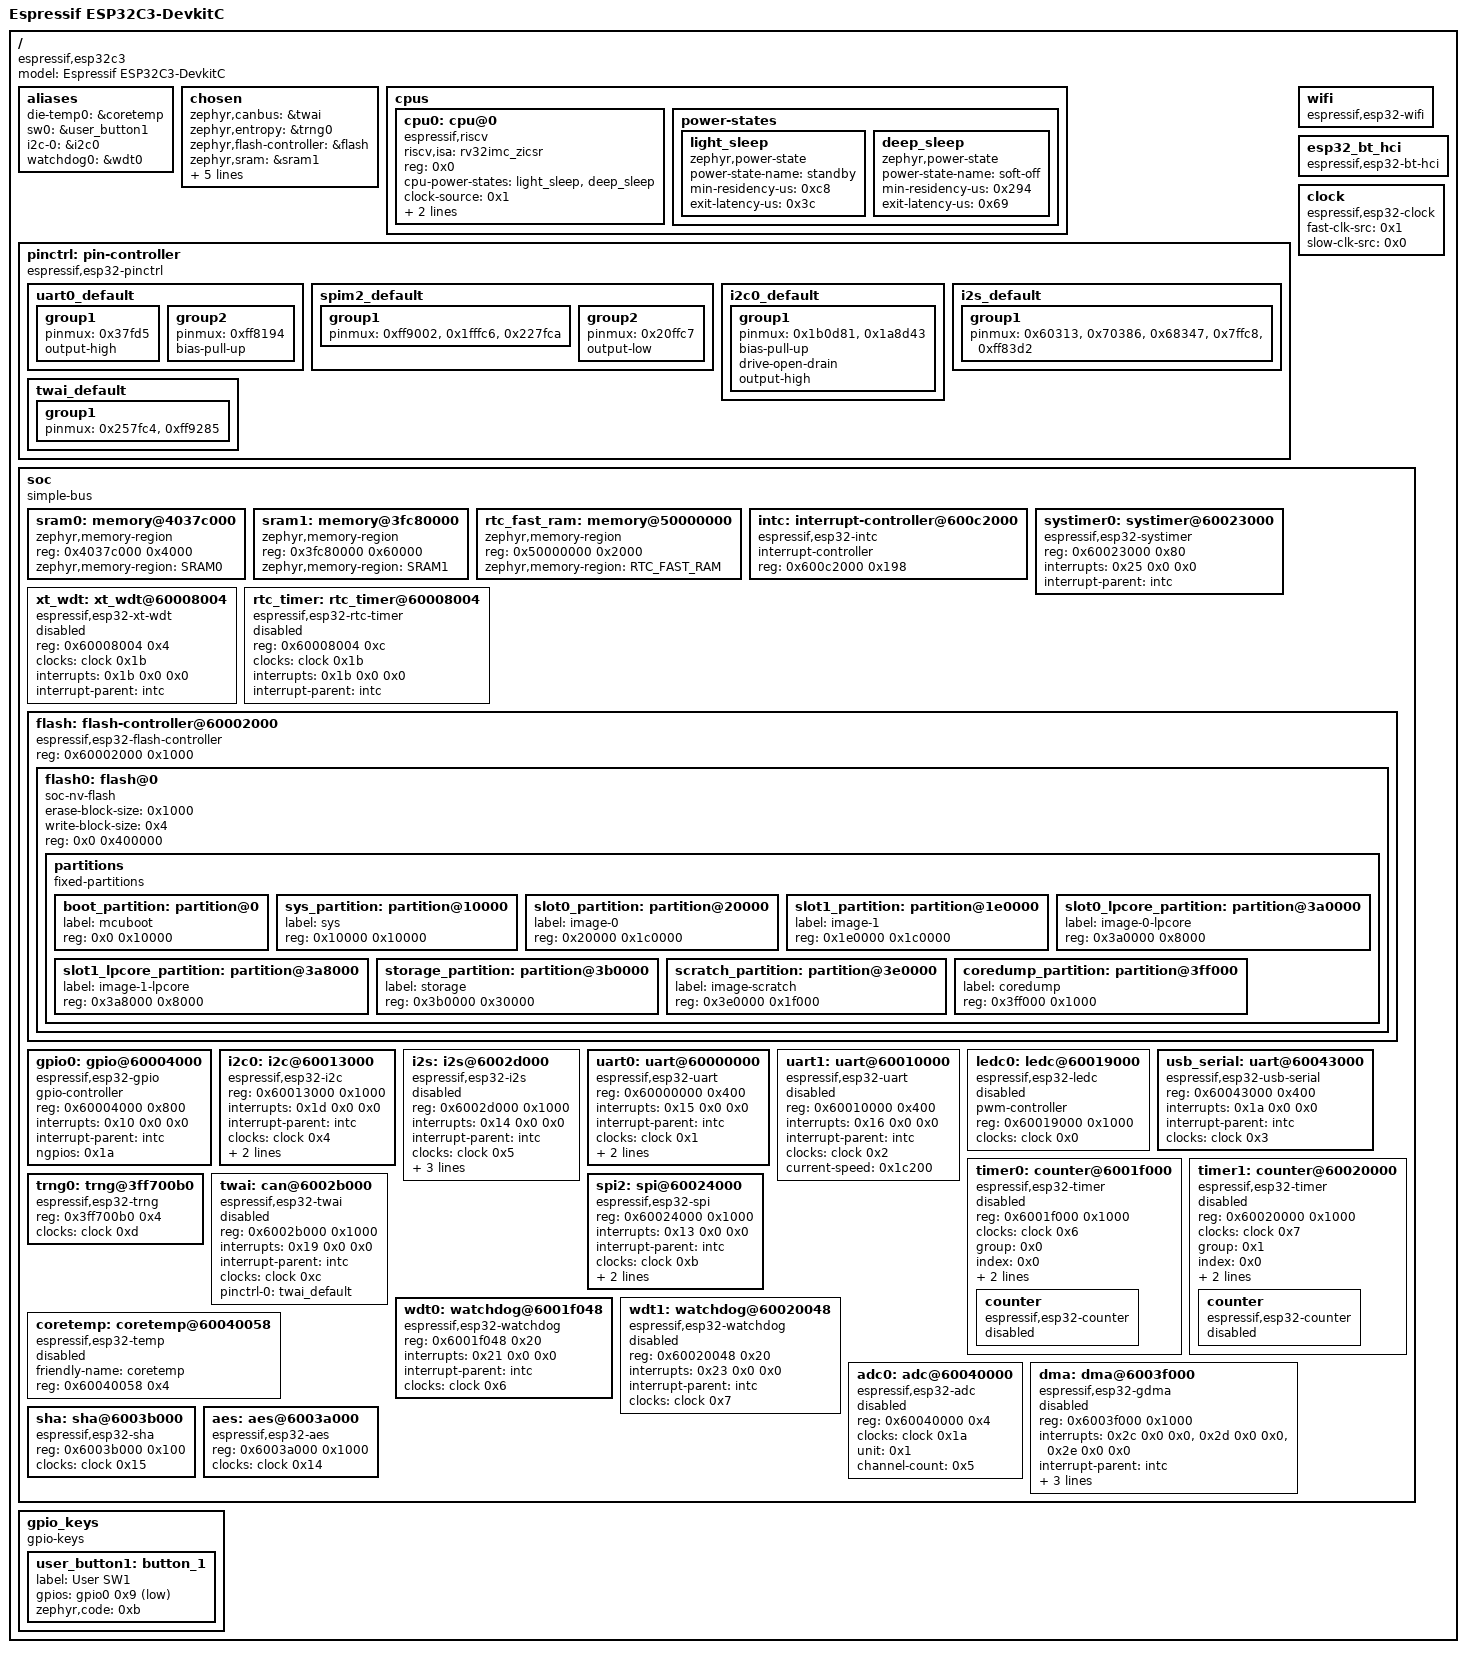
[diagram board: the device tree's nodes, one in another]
/dts-v1/;

/* node '/' defined in zephyr/dts/riscv/espressif/esp32c3/esp32c3_common.dtsi:15 */
/ {
	#address-cells = < 0x1 >;            /* in zephyr/dts/riscv/espressif/esp32c3/esp32c3_common.dtsi:16 */
	#size-cells = < 0x1 >;               /* in zephyr/dts/riscv/espressif/esp32c3/esp32c3_common.dtsi:17 */
	model = "Espressif ESP32C3-DevkitC"; /* in zephyr/boards/espressif/esp32c3_devkitc/esp32c3_devkitc.dts:15 */
	compatible = "espressif,esp32c3";    /* in zephyr/boards/espressif/esp32c3_devkitc/esp32c3_devkitc.dts:16 */

	/* node '/aliases' defined in zephyr/dts/riscv/espressif/esp32c3/esp32c3_common.dtsi:19 */
	aliases {
		die-temp0 = &coretemp; /* in zephyr/dts/riscv/espressif/esp32c3/esp32c3_common.dtsi:20 */
		sw0 = &user_button1;   /* in zephyr/boards/espressif/esp32c3_devkitc/esp32c3_devkitc.dts:28 */
		i2c-0 = &i2c0;         /* in zephyr/boards/espressif/esp32c3_devkitc/esp32c3_devkitc.dts:29 */
		watchdog0 = &wdt0;     /* in zephyr/boards/espressif/esp32c3_devkitc/esp32c3_devkitc.dts:30 */
	};

	/* node '/chosen' defined in zephyr/dts/riscv/espressif/esp32c3/esp32c3_common.dtsi:23 */
	chosen {
		zephyr,canbus = &twai;                    /* in zephyr/dts/riscv/espressif/esp32c3/esp32c3_common.dtsi:24 */
		zephyr,entropy = &trng0;                  /* in zephyr/dts/riscv/espressif/esp32c3/esp32c3_common.dtsi:25 */
		zephyr,flash-controller = &flash;         /* in zephyr/dts/riscv/espressif/esp32c3/esp32c3_common.dtsi:26 */
		zephyr,sram = &sram1;                     /* in zephyr/boards/espressif/esp32c3_devkitc/esp32c3_devkitc.dts:19 */
		zephyr,console = &uart0;                  /* in zephyr/boards/espressif/esp32c3_devkitc/esp32c3_devkitc.dts:20 */
		zephyr,shell-uart = &uart0;               /* in zephyr/boards/espressif/esp32c3_devkitc/esp32c3_devkitc.dts:21 */
		zephyr,flash = &flash0;                   /* in zephyr/boards/espressif/esp32c3_devkitc/esp32c3_devkitc.dts:22 */
		zephyr,code-partition = &slot0_partition; /* in zephyr/boards/espressif/esp32c3_devkitc/esp32c3_devkitc.dts:23 */
		zephyr,bt-hci = &esp32_bt_hci;            /* in zephyr/boards/espressif/esp32c3_devkitc/esp32c3_devkitc.dts:24 */
	};

	/* node '/cpus' defined in zephyr/dts/riscv/espressif/esp32c3/esp32c3_common.dtsi:30 */
	cpus {
		#address-cells = < 0x1 >; /* in zephyr/dts/riscv/espressif/esp32c3/esp32c3_common.dtsi:31 */
		#size-cells = < 0x0 >;    /* in zephyr/dts/riscv/espressif/esp32c3/esp32c3_common.dtsi:32 */

		/* node '/cpus/cpu@0' defined in zephyr/dts/riscv/espressif/esp32c3/esp32c3_common.dtsi:34 */
		cpu0: cpu@0 {
			device_type = "cpu";                             /* in zephyr/dts/riscv/espressif/esp32c3/esp32c3_common.dtsi:35 */
			compatible = "espressif,riscv",
			             "riscv";                            /* in zephyr/dts/riscv/espressif/esp32c3/esp32c3_common.dtsi:36 */
			riscv,isa = "rv32imc_zicsr";                     /* in zephyr/dts/riscv/espressif/esp32c3/esp32c3_common.dtsi:37 */
			reg = < 0x0 >;                                   /* in zephyr/dts/riscv/espressif/esp32c3/esp32c3_common.dtsi:38 */
			cpu-power-states = < &light_sleep &deep_sleep >; /* in zephyr/dts/riscv/espressif/esp32c3/esp32c3_common.dtsi:39 */
			clock-source = < 0x1 >;                          /* in zephyr/dts/riscv/espressif/esp32c3/esp32c3_common.dtsi:40 */
			clock-frequency = < 0x9896800 >;                 /* in zephyr/dts/riscv/espressif/esp32c3/esp32c3_common.dtsi:41 */
			xtal-freq = < 0x2625a00 >;                       /* in zephyr/dts/riscv/espressif/esp32c3/esp32c3_common.dtsi:42 */
		};

		/* node '/cpus/power-states' defined in zephyr/dts/riscv/espressif/esp32c3/esp32c3_common.dtsi:45 */
		power-states {

			/* node '/cpus/power-states/light_sleep' defined in zephyr/dts/riscv/espressif/esp32c3/esp32c3_common.dtsi:46 */
			light_sleep: light_sleep {
				compatible = "zephyr,power-state"; /* in zephyr/dts/riscv/espressif/esp32c3/esp32c3_common.dtsi:47 */
				power-state-name = "standby";      /* in zephyr/dts/riscv/espressif/esp32c3/esp32c3_common.dtsi:48 */
				min-residency-us = < 0xc8 >;       /* in zephyr/dts/riscv/espressif/esp32c3/esp32c3_common.dtsi:49 */
				exit-latency-us = < 0x3c >;        /* in zephyr/dts/riscv/espressif/esp32c3/esp32c3_common.dtsi:50 */
				phandle = < 0x1 >;                 /* in zephyr/dts/riscv/espressif/esp32c3/esp32c3_common.dtsi:39 */
			};

			/* node '/cpus/power-states/deep_sleep' defined in zephyr/dts/riscv/espressif/esp32c3/esp32c3_common.dtsi:53 */
			deep_sleep: deep_sleep {
				compatible = "zephyr,power-state"; /* in zephyr/dts/riscv/espressif/esp32c3/esp32c3_common.dtsi:54 */
				power-state-name = "soft-off";     /* in zephyr/dts/riscv/espressif/esp32c3/esp32c3_common.dtsi:55 */
				min-residency-us = < 0x294 >;      /* in zephyr/dts/riscv/espressif/esp32c3/esp32c3_common.dtsi:56 */
				exit-latency-us = < 0x69 >;        /* in zephyr/dts/riscv/espressif/esp32c3/esp32c3_common.dtsi:57 */
				phandle = < 0x2 >;                 /* in zephyr/dts/riscv/espressif/esp32c3/esp32c3_common.dtsi:39 */
			};
		};
	};

	/* node '/pin-controller' defined in zephyr/dts/riscv/espressif/esp32c3/esp32c3_common.dtsi:62 */
	pinctrl: pin-controller {
		compatible = "espressif,esp32-pinctrl"; /* in zephyr/dts/riscv/espressif/esp32c3/esp32c3_common.dtsi:63 */
		status = "okay";                        /* in zephyr/dts/riscv/espressif/esp32c3/esp32c3_common.dtsi:64 */

		/* node '/pin-controller/uart0_default' defined in zephyr/boards/espressif/esp32c3_devkitc/esp32c3_devkitc-pinctrl.dtsi:12 */
		uart0_default: uart0_default {
			phandle = < 0x8 >; /* in zephyr/boards/espressif/esp32c3_devkitc/esp32c3_devkitc.dts:47 */

			/* node '/pin-controller/uart0_default/group1' defined in zephyr/boards/espressif/esp32c3_devkitc/esp32c3_devkitc-pinctrl.dtsi:13 */
			group1 {
				pinmux = < 0x37fd5 >; /* in zephyr/boards/espressif/esp32c3_devkitc/esp32c3_devkitc-pinctrl.dtsi:14 */
				output-high;          /* in zephyr/boards/espressif/esp32c3_devkitc/esp32c3_devkitc-pinctrl.dtsi:15 */
			};

			/* node '/pin-controller/uart0_default/group2' defined in zephyr/boards/espressif/esp32c3_devkitc/esp32c3_devkitc-pinctrl.dtsi:18 */
			group2 {
				pinmux = < 0xff8194 >; /* in zephyr/boards/espressif/esp32c3_devkitc/esp32c3_devkitc-pinctrl.dtsi:19 */
				bias-pull-up;          /* in zephyr/boards/espressif/esp32c3_devkitc/esp32c3_devkitc-pinctrl.dtsi:20 */
			};
		};

		/* node '/pin-controller/spim2_default' defined in zephyr/boards/espressif/esp32c3_devkitc/esp32c3_devkitc-pinctrl.dtsi:24 */
		spim2_default: spim2_default {
			phandle = < 0xa >; /* in zephyr/boards/espressif/esp32c3_devkitc/esp32c3_devkitc.dts:76 */

			/* node '/pin-controller/spim2_default/group1' defined in zephyr/boards/espressif/esp32c3_devkitc/esp32c3_devkitc-pinctrl.dtsi:25 */
			group1 {
				pinmux = < 0xff9002 >,
				         < 0x1fffc6 >,
				         < 0x227fca >; /* in zephyr/boards/espressif/esp32c3_devkitc/esp32c3_devkitc-pinctrl.dtsi:26 */
			};

			/* node '/pin-controller/spim2_default/group2' defined in zephyr/boards/espressif/esp32c3_devkitc/esp32c3_devkitc-pinctrl.dtsi:31 */
			group2 {
				pinmux = < 0x20ffc7 >; /* in zephyr/boards/espressif/esp32c3_devkitc/esp32c3_devkitc-pinctrl.dtsi:32 */
				output-low;            /* in zephyr/boards/espressif/esp32c3_devkitc/esp32c3_devkitc-pinctrl.dtsi:33 */
			};
		};

		/* node '/pin-controller/i2c0_default' defined in zephyr/boards/espressif/esp32c3_devkitc/esp32c3_devkitc-pinctrl.dtsi:37 */
		i2c0_default: i2c0_default {
			phandle = < 0x5 >; /* in zephyr/boards/espressif/esp32c3_devkitc/esp32c3_devkitc.dts:59 */

			/* node '/pin-controller/i2c0_default/group1' defined in zephyr/boards/espressif/esp32c3_devkitc/esp32c3_devkitc-pinctrl.dtsi:38 */
			group1 {
				pinmux = < 0x1b0d81 >,
				         < 0x1a8d43 >; /* in zephyr/boards/espressif/esp32c3_devkitc/esp32c3_devkitc-pinctrl.dtsi:39 */
				bias-pull-up;          /* in zephyr/boards/espressif/esp32c3_devkitc/esp32c3_devkitc-pinctrl.dtsi:41 */
				drive-open-drain;      /* in zephyr/boards/espressif/esp32c3_devkitc/esp32c3_devkitc-pinctrl.dtsi:42 */
				output-high;           /* in zephyr/boards/espressif/esp32c3_devkitc/esp32c3_devkitc-pinctrl.dtsi:43 */
			};
		};

		/* node '/pin-controller/i2s_default' defined in zephyr/boards/espressif/esp32c3_devkitc/esp32c3_devkitc-pinctrl.dtsi:47 */
		i2s_default: i2s_default {
			phandle = < 0x7 >; /* in zephyr/boards/espressif/esp32c3_devkitc/esp32c3_devkitc.dts:64 */

			/* node '/pin-controller/i2s_default/group1' defined in zephyr/boards/espressif/esp32c3_devkitc/esp32c3_devkitc-pinctrl.dtsi:48 */
			group1 {
				pinmux = < 0x60313 >,
				         < 0x70386 >,
				         < 0x68347 >,
				         < 0x7ffc8 >,
				         < 0xff83d2 >; /* in zephyr/boards/espressif/esp32c3_devkitc/esp32c3_devkitc-pinctrl.dtsi:49 */
			};
		};

		/* node '/pin-controller/twai_default' defined in zephyr/boards/espressif/esp32c3_devkitc/esp32c3_devkitc-pinctrl.dtsi:57 */
		twai_default: twai_default {
			phandle = < 0x9 >; /* in zephyr/boards/espressif/esp32c3_devkitc/esp32c3_devkitc.dts:99 */

			/* node '/pin-controller/twai_default/group1' defined in zephyr/boards/espressif/esp32c3_devkitc/esp32c3_devkitc-pinctrl.dtsi:58 */
			group1 {
				pinmux = < 0x257fc4 >,
				         < 0xff9285 >; /* in zephyr/boards/espressif/esp32c3_devkitc/esp32c3_devkitc-pinctrl.dtsi:59 */
			};
		};
	};

	/* node '/wifi' defined in zephyr/dts/riscv/espressif/esp32c3/esp32c3_common.dtsi:67 */
	wifi: wifi {
		compatible = "espressif,esp32-wifi"; /* in zephyr/dts/riscv/espressif/esp32c3/esp32c3_common.dtsi:68 */
		status = "okay";                     /* in zephyr/boards/espressif/esp32c3_devkitc/esp32c3_devkitc.dts:108 */
	};

	/* node '/esp32_bt_hci' defined in zephyr/dts/riscv/espressif/esp32c3/esp32c3_common.dtsi:72 */
	esp32_bt_hci: esp32_bt_hci {
		compatible = "espressif,esp32-bt-hci"; /* in zephyr/dts/riscv/espressif/esp32c3/esp32c3_common.dtsi:73 */
		status = "okay";                       /* in zephyr/boards/espressif/esp32c3_devkitc/esp32c3_devkitc.dts:104 */
	};

	/* node '/clock' defined in zephyr/dts/riscv/espressif/esp32c3/esp32c3_common.dtsi:77 */
	clock: clock {
		compatible = "espressif,esp32-clock"; /* in zephyr/dts/riscv/espressif/esp32c3/esp32c3_common.dtsi:78 */
		fast-clk-src = < 0x1 >;               /* in zephyr/dts/riscv/espressif/esp32c3/esp32c3_common.dtsi:79 */
		slow-clk-src = < 0x0 >;               /* in zephyr/dts/riscv/espressif/esp32c3/esp32c3_common.dtsi:80 */
		#clock-cells = < 0x1 >;               /* in zephyr/dts/riscv/espressif/esp32c3/esp32c3_common.dtsi:81 */
		status = "okay";                      /* in zephyr/dts/riscv/espressif/esp32c3/esp32c3_common.dtsi:82 */
		phandle = < 0x4 >;                    /* in zephyr/dts/riscv/espressif/esp32c3/esp32c3_common.dtsi:129 */
	};

	/* node '/soc' defined in zephyr/dts/riscv/espressif/esp32c3/esp32c3_common.dtsi:85 */
	soc {
		#address-cells = < 0x1 >;  /* in zephyr/dts/riscv/espressif/esp32c3/esp32c3_common.dtsi:86 */
		#size-cells = < 0x1 >;     /* in zephyr/dts/riscv/espressif/esp32c3/esp32c3_common.dtsi:87 */
		compatible = "simple-bus"; /* in zephyr/dts/riscv/espressif/esp32c3/esp32c3_common.dtsi:88 */
		ranges;                    /* in zephyr/dts/riscv/espressif/esp32c3/esp32c3_common.dtsi:89 */

		/* node '/soc/memory@4037c000' defined in zephyr/dts/riscv/espressif/esp32c3/esp32c3_common.dtsi:91 */
		sram0: memory@4037c000 {
			compatible = "zephyr,memory-region",
			             "mmio-sram";            /* in zephyr/dts/riscv/espressif/esp32c3/esp32c3_common.dtsi:92 */
			reg = < 0x4037c000 0x4000 >;         /* in zephyr/dts/riscv/espressif/esp32c3/esp32c3_common.dtsi:93 */
			zephyr,memory-region = "SRAM0";      /* in zephyr/dts/riscv/espressif/esp32c3/esp32c3_common.dtsi:94 */
		};

		/* node '/soc/memory@3fc80000' defined in zephyr/dts/riscv/espressif/esp32c3/esp32c3_common.dtsi:97 */
		sram1: memory@3fc80000 {
			compatible = "zephyr,memory-region",
			             "mmio-sram";            /* in zephyr/dts/riscv/espressif/esp32c3/esp32c3_common.dtsi:98 */
			reg = < 0x3fc80000 0x60000 >;        /* in zephyr/dts/riscv/espressif/esp32c3/esp32c3_common.dtsi:99 */
			zephyr,memory-region = "SRAM1";      /* in zephyr/dts/riscv/espressif/esp32c3/esp32c3_common.dtsi:100 */
		};

		/* node '/soc/memory@50000000' defined in zephyr/dts/riscv/espressif/esp32c3/esp32c3_common.dtsi:103 */
		rtc_fast_ram: memory@50000000 {
			compatible = "zephyr,memory-region",
			             "mmio-sram";              /* in zephyr/dts/riscv/espressif/esp32c3/esp32c3_common.dtsi:104 */
			reg = < 0x50000000 0x2000 >;           /* in zephyr/dts/riscv/espressif/esp32c3/esp32c3_common.dtsi:105 */
			zephyr,memory-region = "RTC_FAST_RAM"; /* in zephyr/dts/riscv/espressif/esp32c3/esp32c3_common.dtsi:106 */
		};

		/* node '/soc/interrupt-controller@600c2000' defined in zephyr/dts/riscv/espressif/esp32c3/esp32c3_common.dtsi:109 */
		intc: interrupt-controller@600c2000 {
			compatible = "espressif,esp32-intc"; /* in zephyr/dts/riscv/espressif/esp32c3/esp32c3_common.dtsi:110 */
			#address-cells = < 0x0 >;            /* in zephyr/dts/riscv/espressif/esp32c3/esp32c3_common.dtsi:111 */
			#interrupt-cells = < 0x3 >;          /* in zephyr/dts/riscv/espressif/esp32c3/esp32c3_common.dtsi:112 */
			interrupt-controller;                /* in zephyr/dts/riscv/espressif/esp32c3/esp32c3_common.dtsi:113 */
			reg = < 0x600c2000 0x198 >;          /* in zephyr/dts/riscv/espressif/esp32c3/esp32c3_common.dtsi:114 */
			status = "okay";                     /* in zephyr/dts/riscv/espressif/esp32c3/esp32c3_common.dtsi:115 */
			phandle = < 0x3 >;                   /* in zephyr/dts/riscv/espressif/esp32c3/esp32c3_common.dtsi:122 */
		};

		/* node '/soc/systimer@60023000' defined in zephyr/dts/riscv/espressif/esp32c3/esp32c3_common.dtsi:118 */
		systimer0: systimer@60023000 {
			compatible = "espressif,esp32-systimer"; /* in zephyr/dts/riscv/espressif/esp32c3/esp32c3_common.dtsi:119 */
			reg = < 0x60023000 0x80 >;               /* in zephyr/dts/riscv/espressif/esp32c3/esp32c3_common.dtsi:120 */
			interrupts = < 0x25 0x0 0x0 >;           /* in zephyr/dts/riscv/espressif/esp32c3/esp32c3_common.dtsi:121 */
			interrupt-parent = < &intc >;            /* in zephyr/dts/riscv/espressif/esp32c3/esp32c3_common.dtsi:122 */
			status = "okay";                         /* in zephyr/dts/riscv/espressif/esp32c3/esp32c3_common.dtsi:123 */
		};

		/* node '/soc/xt_wdt@60008004' defined in zephyr/dts/riscv/espressif/esp32c3/esp32c3_common.dtsi:126 */
		xt_wdt: xt_wdt@60008004 {
			compatible = "espressif,esp32-xt-wdt"; /* in zephyr/dts/riscv/espressif/esp32c3/esp32c3_common.dtsi:127 */
			reg = < 0x60008004 0x4 >;              /* in zephyr/dts/riscv/espressif/esp32c3/esp32c3_common.dtsi:128 */
			clocks = < &clock 0x1b >;              /* in zephyr/dts/riscv/espressif/esp32c3/esp32c3_common.dtsi:129 */
			interrupts = < 0x1b 0x0 0x0 >;         /* in zephyr/dts/riscv/espressif/esp32c3/esp32c3_common.dtsi:130 */
			interrupt-parent = < &intc >;          /* in zephyr/dts/riscv/espressif/esp32c3/esp32c3_common.dtsi:131 */
			status = "disabled";                   /* in zephyr/dts/riscv/espressif/esp32c3/esp32c3_common.dtsi:132 */
		};

		/* node '/soc/rtc_timer@60008004' defined in zephyr/dts/riscv/espressif/esp32c3/esp32c3_common.dtsi:135 */
		rtc_timer: rtc_timer@60008004 {
			reg = < 0x60008004 0xc >;                 /* in zephyr/dts/riscv/espressif/esp32c3/esp32c3_common.dtsi:136 */
			compatible = "espressif,esp32-rtc-timer"; /* in zephyr/dts/riscv/espressif/esp32c3/esp32c3_common.dtsi:137 */
			clocks = < &clock 0x1b >;                 /* in zephyr/dts/riscv/espressif/esp32c3/esp32c3_common.dtsi:138 */
			interrupts = < 0x1b 0x0 0x0 >;            /* in zephyr/dts/riscv/espressif/esp32c3/esp32c3_common.dtsi:139 */
			interrupt-parent = < &intc >;             /* in zephyr/dts/riscv/espressif/esp32c3/esp32c3_common.dtsi:140 */
			status = "disabled";                      /* in zephyr/dts/riscv/espressif/esp32c3/esp32c3_common.dtsi:141 */
		};

		/* node '/soc/flash-controller@60002000' defined in zephyr/dts/riscv/espressif/esp32c3/esp32c3_common.dtsi:144 */
		flash: flash-controller@60002000 {
			compatible = "espressif,esp32-flash-controller"; /* in zephyr/dts/riscv/espressif/esp32c3/esp32c3_common.dtsi:145 */
			reg = < 0x60002000 0x1000 >;                     /* in zephyr/dts/riscv/espressif/esp32c3/esp32c3_common.dtsi:146 */
			#address-cells = < 0x1 >;                        /* in zephyr/dts/riscv/espressif/esp32c3/esp32c3_common.dtsi:148 */
			#size-cells = < 0x1 >;                           /* in zephyr/dts/riscv/espressif/esp32c3/esp32c3_common.dtsi:149 */

			/* node '/soc/flash-controller@60002000/flash@0' defined in zephyr/dts/riscv/espressif/esp32c3/esp32c3_common.dtsi:151 */
			flash0: flash@0 {
				compatible = "soc-nv-flash";   /* in zephyr/dts/riscv/espressif/esp32c3/esp32c3_common.dtsi:152 */
				erase-block-size = < 0x1000 >; /* in zephyr/dts/riscv/espressif/esp32c3/esp32c3_common.dtsi:153 */
				write-block-size = < 0x4 >;    /* in zephyr/dts/riscv/espressif/esp32c3/esp32c3_common.dtsi:154 */
				reg = < 0x0 0x400000 >;        /* in zephyr/dts/riscv/espressif/esp32c3/esp32c3_wroom_n4.dtsi:11 */

				/* node '/soc/flash-controller@60002000/flash@0/partitions' defined in zephyr/dts/vendor/espressif/partitions_0x0_default_4M.dtsi:8 */
				partitions {
					compatible = "fixed-partitions"; /* in zephyr/dts/vendor/espressif/partitions_0x0_default_4M.dtsi:9 */
					#address-cells = < 0x1 >;        /* in zephyr/dts/vendor/espressif/partitions_0x0_default_4M.dtsi:10 */
					#size-cells = < 0x1 >;           /* in zephyr/dts/vendor/espressif/partitions_0x0_default_4M.dtsi:11 */

					/* node '/soc/flash-controller@60002000/flash@0/partitions/partition@0' defined in zephyr/dts/vendor/espressif/partitions_0x0_default_4M.dtsi:13 */
					boot_partition: partition@0 {
						label = "mcuboot";     /* in zephyr/dts/vendor/espressif/partitions_0x0_default_4M.dtsi:14 */
						reg = < 0x0 0x10000 >; /* in zephyr/dts/vendor/espressif/partitions_0x0_default_4M.dtsi:15 */
					};

					/* node '/soc/flash-controller@60002000/flash@0/partitions/partition@10000' defined in zephyr/dts/vendor/espressif/partitions_0x0_default_4M.dtsi:18 */
					sys_partition: partition@10000 {
						label = "sys";             /* in zephyr/dts/vendor/espressif/partitions_0x0_default_4M.dtsi:19 */
						reg = < 0x10000 0x10000 >; /* in zephyr/dts/vendor/espressif/partitions_0x0_default_4M.dtsi:20 */
					};

					/* node '/soc/flash-controller@60002000/flash@0/partitions/partition@20000' defined in zephyr/dts/vendor/espressif/partitions_0x0_default_4M.dtsi:23 */
					slot0_partition: partition@20000 {
						label = "image-0";          /* in zephyr/dts/vendor/espressif/partitions_0x0_default_4M.dtsi:24 */
						reg = < 0x20000 0x1c0000 >; /* in zephyr/dts/vendor/espressif/partitions_0x0_default_4M.dtsi:25 */
					};

					/* node '/soc/flash-controller@60002000/flash@0/partitions/partition@1e0000' defined in zephyr/dts/vendor/espressif/partitions_0x0_default_4M.dtsi:28 */
					slot1_partition: partition@1e0000 {
						label = "image-1";           /* in zephyr/dts/vendor/espressif/partitions_0x0_default_4M.dtsi:29 */
						reg = < 0x1e0000 0x1c0000 >; /* in zephyr/dts/vendor/espressif/partitions_0x0_default_4M.dtsi:30 */
					};

					/* node '/soc/flash-controller@60002000/flash@0/partitions/partition@3a0000' defined in zephyr/dts/vendor/espressif/partitions_0x0_default_4M.dtsi:33 */
					slot0_lpcore_partition: partition@3a0000 {
						label = "image-0-lpcore";  /* in zephyr/dts/vendor/espressif/partitions_0x0_default_4M.dtsi:34 */
						reg = < 0x3a0000 0x8000 >; /* in zephyr/dts/vendor/espressif/partitions_0x0_default_4M.dtsi:35 */
					};

					/* node '/soc/flash-controller@60002000/flash@0/partitions/partition@3a8000' defined in zephyr/dts/vendor/espressif/partitions_0x0_default_4M.dtsi:38 */
					slot1_lpcore_partition: partition@3a8000 {
						label = "image-1-lpcore";  /* in zephyr/dts/vendor/espressif/partitions_0x0_default_4M.dtsi:39 */
						reg = < 0x3a8000 0x8000 >; /* in zephyr/dts/vendor/espressif/partitions_0x0_default_4M.dtsi:40 */
					};

					/* node '/soc/flash-controller@60002000/flash@0/partitions/partition@3b0000' defined in zephyr/dts/vendor/espressif/partitions_0x0_default_4M.dtsi:43 */
					storage_partition: partition@3b0000 {
						label = "storage";          /* in zephyr/dts/vendor/espressif/partitions_0x0_default_4M.dtsi:44 */
						reg = < 0x3b0000 0x30000 >; /* in zephyr/dts/vendor/espressif/partitions_0x0_default_4M.dtsi:45 */
					};

					/* node '/soc/flash-controller@60002000/flash@0/partitions/partition@3e0000' defined in zephyr/dts/vendor/espressif/partitions_0x0_default_4M.dtsi:48 */
					scratch_partition: partition@3e0000 {
						label = "image-scratch";    /* in zephyr/dts/vendor/espressif/partitions_0x0_default_4M.dtsi:49 */
						reg = < 0x3e0000 0x1f000 >; /* in zephyr/dts/vendor/espressif/partitions_0x0_default_4M.dtsi:50 */
					};

					/* node '/soc/flash-controller@60002000/flash@0/partitions/partition@3ff000' defined in zephyr/dts/vendor/espressif/partitions_0x0_default_4M.dtsi:53 */
					coredump_partition: partition@3ff000 {
						label = "coredump";        /* in zephyr/dts/vendor/espressif/partitions_0x0_default_4M.dtsi:54 */
						reg = < 0x3ff000 0x1000 >; /* in zephyr/dts/vendor/espressif/partitions_0x0_default_4M.dtsi:55 */
					};
				};
			};
		};

		/* node '/soc/gpio@60004000' defined in zephyr/dts/riscv/espressif/esp32c3/esp32c3_common.dtsi:159 */
		gpio0: gpio@60004000 {
			compatible = "espressif,esp32-gpio"; /* in zephyr/dts/riscv/espressif/esp32c3/esp32c3_common.dtsi:160 */
			gpio-controller;                     /* in zephyr/dts/riscv/espressif/esp32c3/esp32c3_common.dtsi:161 */
			#gpio-cells = < 0x2 >;               /* in zephyr/dts/riscv/espressif/esp32c3/esp32c3_common.dtsi:162 */
			reg = < 0x60004000 0x800 >;          /* in zephyr/dts/riscv/espressif/esp32c3/esp32c3_common.dtsi:163 */
			interrupts = < 0x10 0x0 0x0 >;       /* in zephyr/dts/riscv/espressif/esp32c3/esp32c3_common.dtsi:164 */
			interrupt-parent = < &intc >;        /* in zephyr/dts/riscv/espressif/esp32c3/esp32c3_common.dtsi:165 */
			ngpios = < 0x1a >;                   /* in zephyr/dts/riscv/espressif/esp32c3/esp32c3_common.dtsi:171 */
			status = "okay";                     /* in zephyr/boards/espressif/esp32c3_devkitc/esp32c3_devkitc.dts:81 */
			phandle = < 0xb >;                   /* in zephyr/boards/espressif/esp32c3_devkitc/esp32c3_devkitc.dts:38 */
		};

		/* node '/soc/i2c@60013000' defined in zephyr/dts/riscv/espressif/esp32c3/esp32c3_common.dtsi:174 */
		i2c0: i2c@60013000 {
			compatible = "espressif,esp32-i2c"; /* in zephyr/dts/riscv/espressif/esp32c3/esp32c3_common.dtsi:175 */
			#address-cells = < 0x1 >;           /* in zephyr/dts/riscv/espressif/esp32c3/esp32c3_common.dtsi:176 */
			#size-cells = < 0x0 >;              /* in zephyr/dts/riscv/espressif/esp32c3/esp32c3_common.dtsi:177 */
			reg = < 0x60013000 0x1000 >;        /* in zephyr/dts/riscv/espressif/esp32c3/esp32c3_common.dtsi:178 */
			interrupts = < 0x1d 0x0 0x0 >;      /* in zephyr/dts/riscv/espressif/esp32c3/esp32c3_common.dtsi:179 */
			interrupt-parent = < &intc >;       /* in zephyr/dts/riscv/espressif/esp32c3/esp32c3_common.dtsi:180 */
			clocks = < &clock 0x4 >;            /* in zephyr/dts/riscv/espressif/esp32c3/esp32c3_common.dtsi:181 */
			status = "okay";                    /* in zephyr/boards/espressif/esp32c3_devkitc/esp32c3_devkitc.dts:57 */
			clock-frequency = < 0x186a0 >;      /* in zephyr/boards/espressif/esp32c3_devkitc/esp32c3_devkitc.dts:58 */
			pinctrl-0 = < &i2c0_default >;      /* in zephyr/boards/espressif/esp32c3_devkitc/esp32c3_devkitc.dts:59 */
			pinctrl-names = "default";          /* in zephyr/boards/espressif/esp32c3_devkitc/esp32c3_devkitc.dts:60 */
		};

		/* node '/soc/i2s@6002d000' defined in zephyr/dts/riscv/espressif/esp32c3/esp32c3_common.dtsi:185 */
		i2s: i2s@6002d000 {
			compatible = "espressif,esp32-i2s"; /* in zephyr/dts/riscv/espressif/esp32c3/esp32c3_common.dtsi:186 */
			#address-cells = < 0x1 >;           /* in zephyr/dts/riscv/espressif/esp32c3/esp32c3_common.dtsi:187 */
			#size-cells = < 0x0 >;              /* in zephyr/dts/riscv/espressif/esp32c3/esp32c3_common.dtsi:188 */
			reg = < 0x6002d000 0x1000 >;        /* in zephyr/dts/riscv/espressif/esp32c3/esp32c3_common.dtsi:189 */
			interrupts = < 0x14 0x0 0x0 >;      /* in zephyr/dts/riscv/espressif/esp32c3/esp32c3_common.dtsi:190 */
			interrupt-parent = < &intc >;       /* in zephyr/dts/riscv/espressif/esp32c3/esp32c3_common.dtsi:191 */
			clocks = < &clock 0x5 >;            /* in zephyr/dts/riscv/espressif/esp32c3/esp32c3_common.dtsi:192 */
			dmas = < &dma 0x2 >,
			       < &dma 0x3 >;                /* in zephyr/dts/riscv/espressif/esp32c3/esp32c3_common.dtsi:193 */
			dma-names = "rx",
			            "tx";                   /* in zephyr/dts/riscv/espressif/esp32c3/esp32c3_common.dtsi:194 */
			unit = < 0x0 >;                     /* in zephyr/dts/riscv/espressif/esp32c3/esp32c3_common.dtsi:195 */
			status = "disabled";                /* in zephyr/dts/riscv/espressif/esp32c3/esp32c3_common.dtsi:196 */
			pinctrl-0 = < &i2s_default >;       /* in zephyr/boards/espressif/esp32c3_devkitc/esp32c3_devkitc.dts:64 */
			pinctrl-names = "default";          /* in zephyr/boards/espressif/esp32c3_devkitc/esp32c3_devkitc.dts:65 */
		};

		/* node '/soc/uart@60000000' defined in zephyr/dts/riscv/espressif/esp32c3/esp32c3_common.dtsi:199 */
		uart0: uart@60000000 {
			compatible = "espressif,esp32-uart"; /* in zephyr/dts/riscv/espressif/esp32c3/esp32c3_common.dtsi:200 */
			reg = < 0x60000000 0x400 >;          /* in zephyr/dts/riscv/espressif/esp32c3/esp32c3_common.dtsi:201 */
			interrupts = < 0x15 0x0 0x0 >;       /* in zephyr/dts/riscv/espressif/esp32c3/esp32c3_common.dtsi:203 */
			interrupt-parent = < &intc >;        /* in zephyr/dts/riscv/espressif/esp32c3/esp32c3_common.dtsi:204 */
			clocks = < &clock 0x1 >;             /* in zephyr/dts/riscv/espressif/esp32c3/esp32c3_common.dtsi:205 */
			status = "okay";                     /* in zephyr/boards/espressif/esp32c3_devkitc/esp32c3_devkitc.dts:45 */
			current-speed = < 0x1c200 >;         /* in zephyr/boards/espressif/esp32c3_devkitc/esp32c3_devkitc.dts:46 */
			pinctrl-0 = < &uart0_default >;      /* in zephyr/boards/espressif/esp32c3_devkitc/esp32c3_devkitc.dts:47 */
			pinctrl-names = "default";           /* in zephyr/boards/espressif/esp32c3_devkitc/esp32c3_devkitc.dts:48 */
		};

		/* node '/soc/uart@60010000' defined in zephyr/dts/riscv/espressif/esp32c3/esp32c3_common.dtsi:208 */
		uart1: uart@60010000 {
			compatible = "espressif,esp32-uart"; /* in zephyr/dts/riscv/espressif/esp32c3/esp32c3_common.dtsi:209 */
			reg = < 0x60010000 0x400 >;          /* in zephyr/dts/riscv/espressif/esp32c3/esp32c3_common.dtsi:210 */
			status = "disabled";                 /* in zephyr/dts/riscv/espressif/esp32c3/esp32c3_common.dtsi:211 */
			interrupts = < 0x16 0x0 0x0 >;       /* in zephyr/dts/riscv/espressif/esp32c3/esp32c3_common.dtsi:212 */
			interrupt-parent = < &intc >;        /* in zephyr/dts/riscv/espressif/esp32c3/esp32c3_common.dtsi:213 */
			clocks = < &clock 0x2 >;             /* in zephyr/dts/riscv/espressif/esp32c3/esp32c3_common.dtsi:214 */
			current-speed = < 0x1c200 >;         /* in zephyr/dts/riscv/espressif/esp32c3/esp32c3_common.dtsi:215 */
		};

		/* node '/soc/ledc@60019000' defined in zephyr/dts/riscv/espressif/esp32c3/esp32c3_common.dtsi:218 */
		ledc0: ledc@60019000 {
			compatible = "espressif,esp32-ledc"; /* in zephyr/dts/riscv/espressif/esp32c3/esp32c3_common.dtsi:219 */
			pwm-controller;                      /* in zephyr/dts/riscv/espressif/esp32c3/esp32c3_common.dtsi:220 */
			#pwm-cells = < 0x3 >;                /* in zephyr/dts/riscv/espressif/esp32c3/esp32c3_common.dtsi:221 */
			reg = < 0x60019000 0x1000 >;         /* in zephyr/dts/riscv/espressif/esp32c3/esp32c3_common.dtsi:222 */
			clocks = < &clock 0x0 >;             /* in zephyr/dts/riscv/espressif/esp32c3/esp32c3_common.dtsi:223 */
			status = "disabled";                 /* in zephyr/dts/riscv/espressif/esp32c3/esp32c3_common.dtsi:224 */
		};

		/* node '/soc/uart@60043000' defined in zephyr/dts/riscv/espressif/esp32c3/esp32c3_common.dtsi:227 */
		usb_serial: uart@60043000 {
			compatible = "espressif,esp32-usb-serial"; /* in zephyr/dts/riscv/espressif/esp32c3/esp32c3_common.dtsi:228 */
			reg = < 0x60043000 0x400 >;                /* in zephyr/dts/riscv/espressif/esp32c3/esp32c3_common.dtsi:229 */
			interrupts = < 0x1a 0x0 0x0 >;             /* in zephyr/dts/riscv/espressif/esp32c3/esp32c3_common.dtsi:231 */
			interrupt-parent = < &intc >;              /* in zephyr/dts/riscv/espressif/esp32c3/esp32c3_common.dtsi:232 */
			clocks = < &clock 0x3 >;                   /* in zephyr/dts/riscv/espressif/esp32c3/esp32c3_common.dtsi:233 */
			status = "okay";                           /* in zephyr/boards/espressif/esp32c3_devkitc/esp32c3_devkitc.dts:53 */
		};

		/* node '/soc/counter@6001f000' defined in zephyr/dts/riscv/espressif/esp32c3/esp32c3_common.dtsi:236 */
		timer0: counter@6001f000 {
			compatible = "espressif,esp32-timer"; /* in zephyr/dts/riscv/espressif/esp32c3/esp32c3_common.dtsi:237 */
			reg = < 0x6001f000 0x1000 >;          /* in zephyr/dts/riscv/espressif/esp32c3/esp32c3_common.dtsi:238 */
			clocks = < &clock 0x6 >;              /* in zephyr/dts/riscv/espressif/esp32c3/esp32c3_common.dtsi:239 */
			group = < 0x0 >;                      /* in zephyr/dts/riscv/espressif/esp32c3/esp32c3_common.dtsi:240 */
			index = < 0x0 >;                      /* in zephyr/dts/riscv/espressif/esp32c3/esp32c3_common.dtsi:241 */
			interrupts = < 0x20 0x0 0x0 >;        /* in zephyr/dts/riscv/espressif/esp32c3/esp32c3_common.dtsi:242 */
			interrupt-parent = < &intc >;         /* in zephyr/dts/riscv/espressif/esp32c3/esp32c3_common.dtsi:243 */
			status = "disabled";                  /* in zephyr/boards/espressif/esp32c3_devkitc/esp32c3_devkitc.dts:89 */

			/* node '/soc/counter@6001f000/counter' defined in zephyr/dts/riscv/espressif/esp32c3/esp32c3_common.dtsi:246 */
			counter {
				compatible = "espressif,esp32-counter"; /* in zephyr/dts/riscv/espressif/esp32c3/esp32c3_common.dtsi:247 */
				status = "disabled";                    /* in zephyr/dts/riscv/espressif/esp32c3/esp32c3_common.dtsi:248 */
			};
		};

		/* node '/soc/counter@60020000' defined in zephyr/dts/riscv/espressif/esp32c3/esp32c3_common.dtsi:252 */
		timer1: counter@60020000 {
			compatible = "espressif,esp32-timer"; /* in zephyr/dts/riscv/espressif/esp32c3/esp32c3_common.dtsi:253 */
			reg = < 0x60020000 0x1000 >;          /* in zephyr/dts/riscv/espressif/esp32c3/esp32c3_common.dtsi:254 */
			clocks = < &clock 0x7 >;              /* in zephyr/dts/riscv/espressif/esp32c3/esp32c3_common.dtsi:255 */
			group = < 0x1 >;                      /* in zephyr/dts/riscv/espressif/esp32c3/esp32c3_common.dtsi:256 */
			index = < 0x0 >;                      /* in zephyr/dts/riscv/espressif/esp32c3/esp32c3_common.dtsi:257 */
			interrupts = < 0x22 0x0 0x0 >;        /* in zephyr/dts/riscv/espressif/esp32c3/esp32c3_common.dtsi:258 */
			interrupt-parent = < &intc >;         /* in zephyr/dts/riscv/espressif/esp32c3/esp32c3_common.dtsi:259 */
			status = "disabled";                  /* in zephyr/boards/espressif/esp32c3_devkitc/esp32c3_devkitc.dts:93 */

			/* node '/soc/counter@60020000/counter' defined in zephyr/dts/riscv/espressif/esp32c3/esp32c3_common.dtsi:262 */
			counter {
				compatible = "espressif,esp32-counter"; /* in zephyr/dts/riscv/espressif/esp32c3/esp32c3_common.dtsi:263 */
				status = "disabled";                    /* in zephyr/dts/riscv/espressif/esp32c3/esp32c3_common.dtsi:264 */
			};
		};

		/* node '/soc/trng@3ff700b0' defined in zephyr/dts/riscv/espressif/esp32c3/esp32c3_common.dtsi:268 */
		trng0: trng@3ff700b0 {
			compatible = "espressif,esp32-trng"; /* in zephyr/dts/riscv/espressif/esp32c3/esp32c3_common.dtsi:269 */
			reg = < 0x3ff700b0 0x4 >;            /* in zephyr/dts/riscv/espressif/esp32c3/esp32c3_common.dtsi:270 */
			clocks = < &clock 0xd >;             /* in zephyr/dts/riscv/espressif/esp32c3/esp32c3_common.dtsi:271 */
			status = "okay";                     /* in zephyr/boards/espressif/esp32c3_devkitc/esp32c3_devkitc.dts:69 */
		};

		/* node '/soc/can@6002b000' defined in zephyr/dts/riscv/espressif/esp32c3/esp32c3_common.dtsi:275 */
		twai: can@6002b000 {
			compatible = "espressif,esp32-twai"; /* in zephyr/dts/riscv/espressif/esp32c3/esp32c3_common.dtsi:276 */
			reg = < 0x6002b000 0x1000 >;         /* in zephyr/dts/riscv/espressif/esp32c3/esp32c3_common.dtsi:277 */
			interrupts = < 0x19 0x0 0x0 >;       /* in zephyr/dts/riscv/espressif/esp32c3/esp32c3_common.dtsi:278 */
			interrupt-parent = < &intc >;        /* in zephyr/dts/riscv/espressif/esp32c3/esp32c3_common.dtsi:279 */
			clocks = < &clock 0xc >;             /* in zephyr/dts/riscv/espressif/esp32c3/esp32c3_common.dtsi:280 */
			status = "disabled";                 /* in zephyr/boards/espressif/esp32c3_devkitc/esp32c3_devkitc.dts:98 */
			pinctrl-0 = < &twai_default >;       /* in zephyr/boards/espressif/esp32c3_devkitc/esp32c3_devkitc.dts:99 */
			pinctrl-names = "default";           /* in zephyr/boards/espressif/esp32c3_devkitc/esp32c3_devkitc.dts:100 */
		};

		/* node '/soc/spi@60024000' defined in zephyr/dts/riscv/espressif/esp32c3/esp32c3_common.dtsi:284 */
		spi2: spi@60024000 {
			compatible = "espressif,esp32-spi"; /* in zephyr/dts/riscv/espressif/esp32c3/esp32c3_common.dtsi:285 */
			reg = < 0x60024000 0x1000 >;        /* in zephyr/dts/riscv/espressif/esp32c3/esp32c3_common.dtsi:286 */
			interrupts = < 0x13 0x0 0x0 >;      /* in zephyr/dts/riscv/espressif/esp32c3/esp32c3_common.dtsi:287 */
			interrupt-parent = < &intc >;       /* in zephyr/dts/riscv/espressif/esp32c3/esp32c3_common.dtsi:288 */
			clocks = < &clock 0xb >;            /* in zephyr/dts/riscv/espressif/esp32c3/esp32c3_common.dtsi:289 */
			dma-host = < 0x0 >;                 /* in zephyr/dts/riscv/espressif/esp32c3/esp32c3_common.dtsi:290 */
			#address-cells = < 0x1 >;           /* in zephyr/boards/espressif/esp32c3_devkitc/esp32c3_devkitc.dts:73 */
			#size-cells = < 0x0 >;              /* in zephyr/boards/espressif/esp32c3_devkitc/esp32c3_devkitc.dts:74 */
			status = "okay";                    /* in zephyr/boards/espressif/esp32c3_devkitc/esp32c3_devkitc.dts:75 */
			pinctrl-0 = < &spim2_default >;     /* in zephyr/boards/espressif/esp32c3_devkitc/esp32c3_devkitc.dts:76 */
			pinctrl-names = "default";          /* in zephyr/boards/espressif/esp32c3_devkitc/esp32c3_devkitc.dts:77 */
		};

		/* node '/soc/watchdog@6001f048' defined in zephyr/dts/riscv/espressif/esp32c3/esp32c3_common.dtsi:294 */
		wdt0: watchdog@6001f048 {
			compatible = "espressif,esp32-watchdog"; /* in zephyr/dts/riscv/espressif/esp32c3/esp32c3_common.dtsi:295 */
			reg = < 0x6001f048 0x20 >;               /* in zephyr/dts/riscv/espressif/esp32c3/esp32c3_common.dtsi:296 */
			interrupts = < 0x21 0x0 0x0 >;           /* in zephyr/dts/riscv/espressif/esp32c3/esp32c3_common.dtsi:297 */
			interrupt-parent = < &intc >;            /* in zephyr/dts/riscv/espressif/esp32c3/esp32c3_common.dtsi:298 */
			clocks = < &clock 0x6 >;                 /* in zephyr/dts/riscv/espressif/esp32c3/esp32c3_common.dtsi:299 */
			status = "okay";                         /* in zephyr/boards/espressif/esp32c3_devkitc/esp32c3_devkitc.dts:85 */
		};

		/* node '/soc/watchdog@60020048' defined in zephyr/dts/riscv/espressif/esp32c3/esp32c3_common.dtsi:303 */
		wdt1: watchdog@60020048 {
			compatible = "espressif,esp32-watchdog"; /* in zephyr/dts/riscv/espressif/esp32c3/esp32c3_common.dtsi:304 */
			reg = < 0x60020048 0x20 >;               /* in zephyr/dts/riscv/espressif/esp32c3/esp32c3_common.dtsi:305 */
			interrupts = < 0x23 0x0 0x0 >;           /* in zephyr/dts/riscv/espressif/esp32c3/esp32c3_common.dtsi:306 */
			interrupt-parent = < &intc >;            /* in zephyr/dts/riscv/espressif/esp32c3/esp32c3_common.dtsi:307 */
			clocks = < &clock 0x7 >;                 /* in zephyr/dts/riscv/espressif/esp32c3/esp32c3_common.dtsi:308 */
			status = "disabled";                     /* in zephyr/dts/riscv/espressif/esp32c3/esp32c3_common.dtsi:309 */
		};

		/* node '/soc/coretemp@60040058' defined in zephyr/dts/riscv/espressif/esp32c3/esp32c3_common.dtsi:312 */
		coretemp: coretemp@60040058 {
			compatible = "espressif,esp32-temp"; /* in zephyr/dts/riscv/espressif/esp32c3/esp32c3_common.dtsi:313 */
			friendly-name = "coretemp";          /* in zephyr/dts/riscv/espressif/esp32c3/esp32c3_common.dtsi:314 */
			reg = < 0x60040058 0x4 >;            /* in zephyr/dts/riscv/espressif/esp32c3/esp32c3_common.dtsi:315 */
			status = "disabled";                 /* in zephyr/dts/riscv/espressif/esp32c3/esp32c3_common.dtsi:316 */
		};

		/* node '/soc/adc@60040000' defined in zephyr/dts/riscv/espressif/esp32c3/esp32c3_common.dtsi:319 */
		adc0: adc@60040000 {
			compatible = "espressif,esp32-adc"; /* in zephyr/dts/riscv/espressif/esp32c3/esp32c3_common.dtsi:320 */
			reg = < 0x60040000 0x4 >;           /* in zephyr/dts/riscv/espressif/esp32c3/esp32c3_common.dtsi:321 */
			clocks = < &clock 0x1a >;           /* in zephyr/dts/riscv/espressif/esp32c3/esp32c3_common.dtsi:322 */
			unit = < 0x1 >;                     /* in zephyr/dts/riscv/espressif/esp32c3/esp32c3_common.dtsi:323 */
			channel-count = < 0x5 >;            /* in zephyr/dts/riscv/espressif/esp32c3/esp32c3_common.dtsi:324 */
			#io-channel-cells = < 0x1 >;        /* in zephyr/dts/riscv/espressif/esp32c3/esp32c3_common.dtsi:325 */
			status = "disabled";                /* in zephyr/dts/riscv/espressif/esp32c3/esp32c3_common.dtsi:326 */
		};

		/* node '/soc/dma@6003f000' defined in zephyr/dts/riscv/espressif/esp32c3/esp32c3_common.dtsi:329 */
		dma: dma@6003f000 {
			compatible = "espressif,esp32-gdma"; /* in zephyr/dts/riscv/espressif/esp32c3/esp32c3_common.dtsi:330 */
			reg = < 0x6003f000 0x1000 >;         /* in zephyr/dts/riscv/espressif/esp32c3/esp32c3_common.dtsi:331 */
			#dma-cells = < 0x1 >;                /* in zephyr/dts/riscv/espressif/esp32c3/esp32c3_common.dtsi:332 */
			interrupts = < 0x2c 0x0 0x0 >,
			             < 0x2d 0x0 0x0 >,
			             < 0x2e 0x0 0x0 >;       /* in zephyr/dts/riscv/espressif/esp32c3/esp32c3_common.dtsi:333 */
			interrupt-parent = < &intc >;        /* in zephyr/dts/riscv/espressif/esp32c3/esp32c3_common.dtsi:336 */
			clocks = < &clock 0x18 >;            /* in zephyr/dts/riscv/espressif/esp32c3/esp32c3_common.dtsi:337 */
			dma-channels = < 0x6 >;              /* in zephyr/dts/riscv/espressif/esp32c3/esp32c3_common.dtsi:338 */
			dma-buf-addr-alignment = < 0x4 >;    /* in zephyr/dts/riscv/espressif/esp32c3/esp32c3_common.dtsi:339 */
			status = "disabled";                 /* in zephyr/dts/riscv/espressif/esp32c3/esp32c3_common.dtsi:340 */
			phandle = < 0x6 >;                   /* in zephyr/dts/riscv/espressif/esp32c3/esp32c3_common.dtsi:193 */
		};

		/* node '/soc/sha@6003b000' defined in zephyr/dts/riscv/espressif/esp32c3/esp32c3_common.dtsi:343 */
		sha: sha@6003b000 {
			compatible = "espressif,esp32-sha"; /* in zephyr/dts/riscv/espressif/esp32c3/esp32c3_common.dtsi:344 */
			reg = < 0x6003b000 0x100 >;         /* in zephyr/dts/riscv/espressif/esp32c3/esp32c3_common.dtsi:345 */
			clocks = < &clock 0x15 >;           /* in zephyr/dts/riscv/espressif/esp32c3/esp32c3_common.dtsi:346 */
			status = "okay";                    /* in zephyr/dts/riscv/espressif/esp32c3/esp32c3_common.dtsi:347 */
		};

		/* node '/soc/aes@6003a000' defined in zephyr/dts/riscv/espressif/esp32c3/esp32c3_common.dtsi:350 */
		aes: aes@6003a000 {
			compatible = "espressif,esp32-aes"; /* in zephyr/dts/riscv/espressif/esp32c3/esp32c3_common.dtsi:351 */
			reg = < 0x6003a000 0x1000 >;        /* in zephyr/dts/riscv/espressif/esp32c3/esp32c3_common.dtsi:352 */
			clocks = < &clock 0x14 >;           /* in zephyr/dts/riscv/espressif/esp32c3/esp32c3_common.dtsi:353 */
			status = "okay";                    /* in zephyr/dts/riscv/espressif/esp32c3/esp32c3_common.dtsi:354 */
		};
	};

	/* node '/gpio_keys' defined in zephyr/boards/espressif/esp32c3_devkitc/esp32c3_devkitc.dts:33 */
	gpio_keys {
		compatible = "gpio-keys"; /* in zephyr/boards/espressif/esp32c3_devkitc/esp32c3_devkitc.dts:34 */

		/* node '/gpio_keys/button_1' defined in zephyr/boards/espressif/esp32c3_devkitc/esp32c3_devkitc.dts:36 */
		user_button1: button_1 {
			label = "User SW1";          /* in zephyr/boards/espressif/esp32c3_devkitc/esp32c3_devkitc.dts:37 */
			gpios = < &gpio0 0x9 0x11 >; /* in zephyr/boards/espressif/esp32c3_devkitc/esp32c3_devkitc.dts:38 */
			zephyr,code = < 0xb >;       /* in zephyr/boards/espressif/esp32c3_devkitc/esp32c3_devkitc.dts:39 */
		};
	};
};
